# f2838x_cpu1_cpu1tocpu2_ipc_regs register map
Vendor: Texas Instruments
Peripheral module from a debugger description file (folder C2000).
Address unit: 16 bits
Registers are 32-bit, read-write, no defined reset value unless marked. A register's access mark holds for its fields unless they carry their own. Offsets are as the file gives them; lines under a group give offsets from that group; [hi:lo] are bit positions; {n}, {i} and the like mark numbered series; 'fields as' and 'values as' point back to an identical list; <NAME> marks a mode.

## CPU1TOCPU2_IPC_REGS_CPU1VIEW — CPU1TOCPU2 IPC Registers
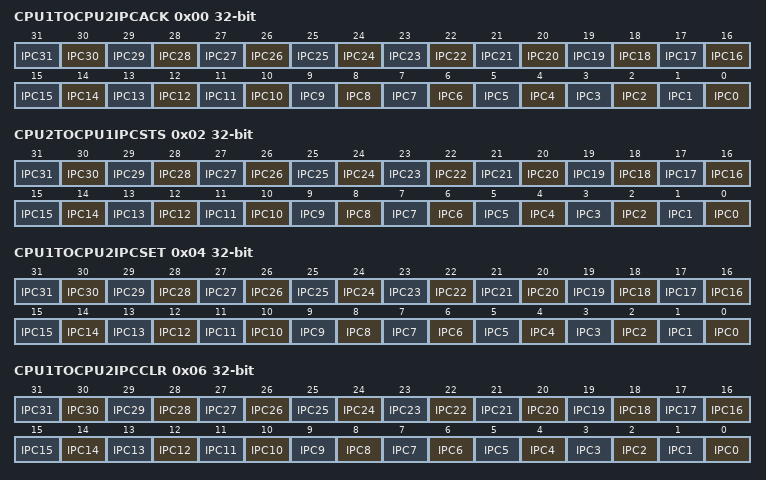
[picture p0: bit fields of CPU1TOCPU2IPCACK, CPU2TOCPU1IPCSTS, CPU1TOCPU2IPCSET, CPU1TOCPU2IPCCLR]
0x00 CPU1TOCPU2IPCACK
  [n] IPC{n} (n=0..31) — Acknowledgement from CPU2 to CPU1TOCPU2IPCFLG.IPC{n} bit
0x02 CPU2TOCPU1IPCSTS ro
  [n] IPC{n} (n=0..31) — IPC{n} Request from CPU1 to CPU2
0x04 CPU1TOCPU2IPCSET
  [n] IPC{n} (n=0..31) — Set CPU2TOCPU1IPCFLG.IPC{n} Flag
0x06 CPU1TOCPU2IPCCLR
  [n] IPC{n} (n=0..31) — Clear CPU2TOCPU1IPCFLG.IPC{n} Flag
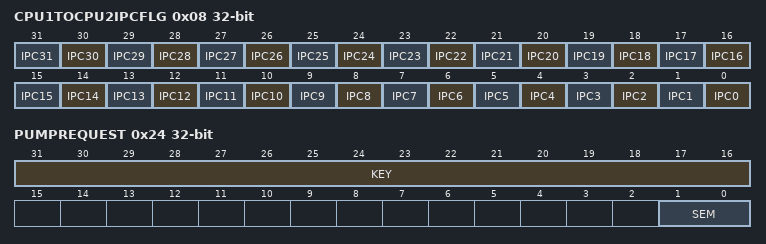
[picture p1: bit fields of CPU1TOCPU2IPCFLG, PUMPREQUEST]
0x08 CPU1TOCPU2IPCFLG ro
  [n] IPC{n} (n=0..31) — CPU2 to CPU1 IPC{n} Flag Status
0x0C IPCCOUNTERL ro
  [31:0] COUNT — IPC Counter's lower 32-bit
0x0E IPCCOUNTERH ro
  [31:0] COUNT — IPC Counter's upper 32-bit
0x10 CPU1TOCPU2IPCSENDCOM ro
  [31:0] COMMAND — Refelects the state of CPU1TOCPU2IPCSENDCOM register
0x12 CPU1TOCPU2IPCSENDADDR ro
  [31:0] ADDRESS — Refelects the state of CPU1TOCPU2IPCSENDADDR register
0x14 CPU1TOCPU2IPCSENDDATA ro
  [31:0] WDATA — Refelects the state of CPU1TOCPU2IPCSENDDATA register
0x16 CPU2TOCPU1IPCREPLY
  [31:0] RDATA — CPU2 to CPU1 IPC Reply
0x18 CPU2TOCPU1IPCRECVCOM
  [31:0] COMMAND — CPU2 to CPU1 IPC Command
0x1A CPU2TOCPU1IPCRECVADDR
  [31:0] ADDRESS — CPU2 to CPU1 IPC Address
0x1C CPU2TOCPU1IPCRECVDATA
  [31:0] WDATA — CPU2 to CPU1 IPC Data
0x1E CPU1TOCPU2IPCREPLY
  [31:0] RDATA — CPU1 to CPU2 IPC Reply
0x20 CPU2TOCPU1IPCBOOTSTS
  [31:0] BOOTSTS — CPU2 to CPU1 IPC Boot Status
0x22 CPU1TOCPU2IPCBOOTMODE
  [31:0] BOOTMODE — CPU1 to CPU2 IPC Boot Mode.
0x24 PUMPREQUEST
  [31:16] KEY — Key Qualifier for writes to this register
  [1:0] SEM — Flash Pump Request Semaphore between CPU1, CPU2 and CM
